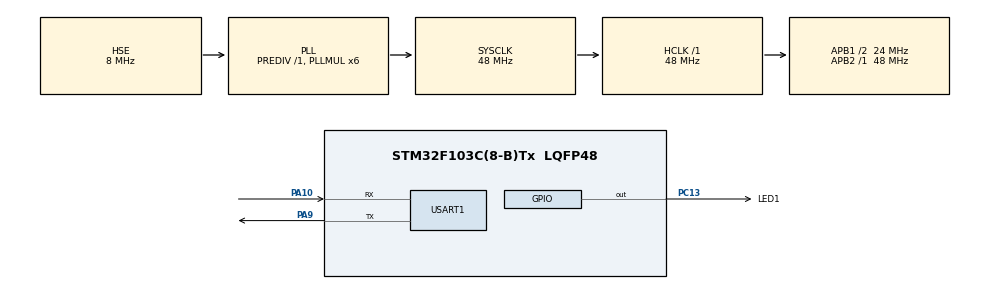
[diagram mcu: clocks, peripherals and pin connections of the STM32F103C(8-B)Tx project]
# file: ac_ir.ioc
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IWDG.Prescaler=IWDG_PRESCALER_256
IWDG.Reload=0xfff
Mcu.Family=STM32F1
Mcu.Name=STM32F103C(8-B)Tx
Mcu.Package=LQFP48
NVIC.PriorityGroup=NVIC_PRIORITYGROUP_4
NVIC.USART1_IRQn=true\:0\:0\:false\:false\:true\:true\:true
PA10.Mode=Asynchronous
PA10.Signal=USART1_RX
PA9.Mode=Asynchronous
PA9.Signal=USART1_TX
PC13-TAMPER-RTC.GPIO_Label=LED1
PC13-TAMPER-RTC.Signal=GPIO_Output
PC14-OSC32_IN.Mode=LSE-External-Oscillator
PC14-OSC32_IN.Signal=RCC_OSC32_IN
PC15-OSC32_OUT.Mode=LSE-External-Oscillator
PC15-OSC32_OUT.Signal=RCC_OSC32_OUT
PD0-OSC_IN.Mode=HSE-External-Oscillator
PD0-OSC_IN.Signal=RCC_OSC_IN
PD1-OSC_OUT.Mode=HSE-External-Oscillator
PD1-OSC_OUT.Signal=RCC_OSC_OUT
ProjectManager.HeapSize=0x200
ProjectManager.StackSize=0x400
ProjectManager.TargetToolchain=STM32CubeIDE
RCC.AHBFreq_Value=48000000
RCC.APB1CLKDivider=RCC_HCLK_DIV2
RCC.APB1Freq_Value=24000000
RCC.APB1TimFreq_Value=48000000
RCC.APB2Freq_Value=48000000
RCC.APB2TimFreq_Value=48000000
RCC.HCLKFreq_Value=48000000
RCC.PLLMUL=RCC_PLL_MUL6
RCC.PLLSourceVirtual=RCC_PLLSOURCE_HSE
RCC.RTCClockSelection=RCC_RTCCLKSOURCE_LSE
RCC.SYSCLKFreq_VALUE=48000000
RCC.SYSCLKSource=RCC_SYSCLKSOURCE_PLLCLK
RCC.USBFreq_Value=48000000
USART1.VirtualMode=VM_ASYNC
VP_IWDG_VS_IWDG.Mode=IWDG_Activate
VP_RTC_No_RTC_Output.Mode=RTC_OUT_NO
VP_RTC_VS_RTC_Activate.Mode=RTC_Enabled
VP_SYS_VS_ND.Mode=No_Debug
board=custom

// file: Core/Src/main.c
/* USER CODE BEGIN Header */
/**
  ******************************************************************************
  * @file           : main.c
  * @brief          : Main program body
  ******************************************************************************
  * @attention
  *
  * <h2><center>&copy; Copyright (c) 2019 STMicroelectronics.
  * All rights reserved.</center></h2>
  *
  * This software component is licensed by ST under BSD 3-Clause license,
  * the "License"; You may not use this file except in compliance with the
  * License. You may obtain a copy of the License at:
  *                        opensource.org/licenses/BSD-3-Clause
  *
  ******************************************************************************
  */
/* USER CODE END Header */

#include "main.h"
#include "iwdg.h"
#include "rtc.h"
#include "usart.h"
#include "gpio.h"

/* USER CODE BEGIN Includes */
#include <stdio.h>
/* USER CODE END Includes */

void SystemClock_Config(void);

int main(void)
{

  /* MCU Configuration--------------------------------------------------------*/

  /* Reset of all peripherals, Initializes the Flash interface and the Systick. */
  HAL_Init();

  /* Configure the system clock */
  SystemClock_Config();

  /* Initialize all configured peripherals */
  MX_GPIO_Init();
  MX_USART1_UART_Init();
  MX_RTC_Init();
  MX_IWDG_Init();
  /* USER CODE BEGIN 2 */

  uint8_t data[64];
  /* USER CODE END 2 */

  /* Infinite loop */
  /* USER CODE BEGIN WHILE */
  uint8_t byte[16];
  MX_USART1_UART_Read(byte, 16);

  while (1)
  {
	  HAL_Delay(1000);

//	  if(MX_USART1_UART_Read(byte, 16) > 0)
//	  {
//		  HAL_GPIO_TogglePin(LED1_GPIO_Port, LED1_Pin);
//		  sprintf((char*)data, (const char*)"RX: %c\n\r", byte);
//		  MX_USART1_UART_Write(data, 7);
//	  }

    /* USER CODE END WHILE */

  }
}

void SystemClock_Config(void)
{
  RCC_OscInitTypeDef RCC_OscInitStruct = {0};
  RCC_ClkInitTypeDef RCC_ClkInitStruct = {0};
  RCC_PeriphCLKInitTypeDef PeriphClkInit = {0};

  /** Initializes the CPU, AHB and APB busses clocks
  */
  RCC_OscInitStruct.OscillatorType = RCC_OSCILLATORTYPE_LSI|RCC_OSCILLATORTYPE_HSE
                              |RCC_OSCILLATORTYPE_LSE;
  RCC_OscInitStruct.HSEState = RCC_HSE_ON;
  RCC_OscInitStruct.HSEPredivValue = RCC_HSE_PREDIV_DIV1;
  RCC_OscInitStruct.LSEState = RCC_LSE_ON;
  RCC_OscInitStruct.HSIState = RCC_HSI_ON;
  RCC_OscInitStruct.LSIState = RCC_LSI_ON;
  RCC_OscInitStruct.PLL.PLLState = RCC_PLL_ON;
  RCC_OscInitStruct.PLL.PLLSource = RCC_PLLSOURCE_HSE;
  RCC_OscInitStruct.PLL.PLLMUL = RCC_PLL_MUL6;
  if (HAL_RCC_OscConfig(&RCC_OscInitStruct) != HAL_OK)
  {
    Error_Handler();
  }
  /** Initializes the CPU, AHB and APB busses clocks
  */
  RCC_ClkInitStruct.ClockType = RCC_CLOCKTYPE_HCLK|RCC_CLOCKTYPE_SYSCLK
                              |RCC_CLOCKTYPE_PCLK1|RCC_CLOCKTYPE_PCLK2;
  RCC_ClkInitStruct.SYSCLKSource = RCC_SYSCLKSOURCE_PLLCLK;
  RCC_ClkInitStruct.AHBCLKDivider = RCC_SYSCLK_DIV1;
  RCC_ClkInitStruct.APB1CLKDivider = RCC_HCLK_DIV2;
  RCC_ClkInitStruct.APB2CLKDivider = RCC_HCLK_DIV1;

  if (HAL_RCC_ClockConfig(&RCC_ClkInitStruct, FLASH_LATENCY_1) != HAL_OK)
  {
    Error_Handler();
  }
  PeriphClkInit.PeriphClockSelection = RCC_PERIPHCLK_RTC;
  PeriphClkInit.RTCClockSelection = RCC_RTCCLKSOURCE_LSE;
  if (HAL_RCCEx_PeriphCLKConfig(&PeriphClkInit) != HAL_OK)
  {
    Error_Handler();
  }
}

void Error_Handler(void)
{
}

/************************ (C) COPYRIGHT STMicroelectronics *****END OF FILE****/
